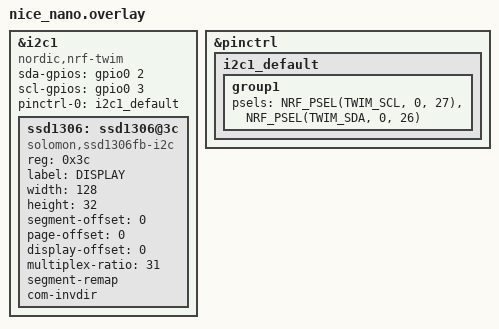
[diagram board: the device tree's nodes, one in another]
&i2c1 {
    compatible = "nordic,nrf-twim";
    status = "okay";

    sda-gpios = <&gpio0 2 GPIO_ACTIVE_HIGH>;
    scl-gpios = <&gpio0 3 GPIO_ACTIVE_HIGH>;

    /* Required for Zephyr 3.5+ */
    pinctrl-0 = <&i2c1_default>;
    pinctrl-names = "default";

    ssd1306: ssd1306@3c {
        compatible = "solomon,ssd1306fb-i2c";
        reg = <0x3c>;
        label = "DISPLAY";

        /* Required SSD1306 properties (Zephyr 3.5) */
        width = <128>;
        height = <32>;
        segment-offset = <0>;
        page-offset = <0>;
        display-offset = <0>;
        multiplex-ratio = <31>;

        /* Recommended flags for Sofle screens */
        segment-remap;
        com-invdir;
    };
};

/* pinctrl group for I2C1 */
&pinctrl {
    i2c1_default: i2c1_default {
        group1 {
            psels = <NRF_PSEL(TWIM_SCL, 0, 27)>,
                    <NRF_PSEL(TWIM_SDA, 0, 26)>;
        };
    };
};
